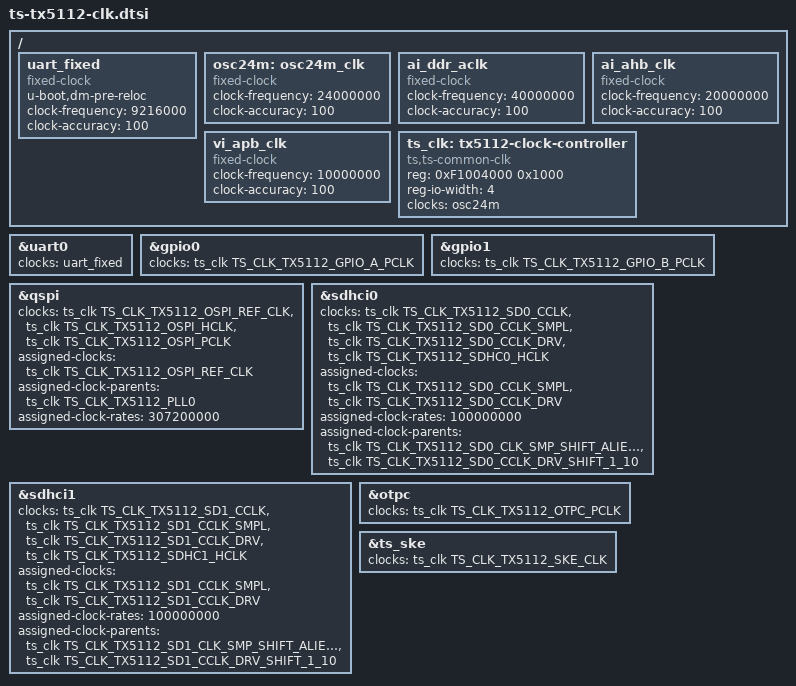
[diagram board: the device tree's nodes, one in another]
// SPDX-License-Identifier: GPL-2.0+
/*
 * dts file for tsingmicro tx51xx
 *
 * Copyright 2022 Beijing Tsingmicro Intelligent Technology Co.,Ltd.
 *
 */

#include <dt-bindings/clock/ts-tx5112-clk.h>
/ {
	uart_fixed: uart_fixed {
		u-boot,dm-pre-reloc;
		compatible = "fixed-clock";
		#clock-cells = <0>;
		clock-frequency = <9216000>;
		clock-accuracy = <100>;
	};
	osc24m: osc24m_clk {
		compatible = "fixed-clock";
		#clock-cells = <0>;
		clock-frequency = <24000000>;
		clock-accuracy = <100>;
	};

	ai_ddr_aclk: ai_ddr_aclk {
		compatible = "fixed-clock";
		#clock-cells = <0>;
		clock-frequency = <40000000>;
		clock-accuracy = <100>;
	};

	ai_ahb_clk: ai_ahb_clk {
			compatible = "fixed-clock";
			#clock-cells = <0>;
			clock-frequency = <20000000>;
			clock-accuracy = <100>;
	};

	vi_apb_clk: vi_apb_clk{
			compatible = "fixed-clock";
			#clock-cells = <0>;
			clock-frequency = <10000000>;
			clock-accuracy = <100>;
	};

	ts_clk: tx5112-clock-controller {
		reg = <0xF1004000 0x1000>;
		reg-io-width = <4>;
		#clock-cells = <1>;
		compatible = "ts,ts-common-clk";
		clocks = <&osc24m>;
	};
};
&uart0 {
	clocks = <&uart_fixed>;
};

&gpio0 {
	clocks = <&ts_clk TS_CLK_TX5112_GPIO_A_PCLK>;
	clock-names = "pclk";
};

&gpio1 {
	clocks = <&ts_clk TS_CLK_TX5112_GPIO_B_PCLK>;
	clock-names = "pclk";
};

&qspi {
	clocks = <&ts_clk TS_CLK_TX5112_OSPI_REF_CLK>, <&ts_clk TS_CLK_TX5112_OSPI_HCLK>, <&ts_clk TS_CLK_TX5112_OSPI_PCLK>;
	clock-names = "ospi_refclk", "ospi_hclk", "ospi_pclk";

	assigned-clocks = <&ts_clk TS_CLK_TX5112_OSPI_REF_CLK>;
	assigned-clock-parents = <&ts_clk TS_CLK_TX5112_PLL0>;
	assigned-clock-rates = <307200000>;
};

&sdhci0 {
	clocks = <&ts_clk TS_CLK_TX5112_SD0_CCLK>, <&ts_clk TS_CLK_TX5112_SD0_CCLK_SMPL>, <&ts_clk TS_CLK_TX5112_SD0_CCLK_DRV>, <&ts_clk TS_CLK_TX5112_SDHC0_HCLK>;
	clock-names = "ciu", "siu", "diu", "hiu";
	assigned-clocks = <&ts_clk TS_CLK_TX5112_SD0_CCLK>;
	assigned-clock-rates = <100000000>;
	assigned-clocks = <&ts_clk TS_CLK_TX5112_SD0_CCLK_SMPL>, <&ts_clk TS_CLK_TX5112_SD0_CCLK_DRV>;
	//assigned-clock-parents = <&ts_clk TS_CLK_TX5112_SD0_CLK_SMP_SHIFT_ALIEND>, <&ts_clk TS_CLK_TX5112_SD0_CLK_SMP_SHIFT_ALIEND>;
	assigned-clock-parents = <&ts_clk TS_CLK_TX5112_SD0_CLK_SMP_SHIFT_ALIEND>, <&ts_clk TS_CLK_TX5112_SD0_CCLK_DRV_SHIFT_1_10>;
};

&sdhci1 {
	clocks = <&ts_clk TS_CLK_TX5112_SD1_CCLK>, <&ts_clk TS_CLK_TX5112_SD1_CCLK_SMPL>, <&ts_clk TS_CLK_TX5112_SD1_CCLK_DRV>, <&ts_clk TS_CLK_TX5112_SDHC1_HCLK>;
	clock-names = "ciu", "siu", "diu", "hiu";
	assigned-clocks = <&ts_clk TS_CLK_TX5112_SD1_CCLK>;
	assigned-clock-rates = <100000000>;
	assigned-clocks = <&ts_clk TS_CLK_TX5112_SD1_CCLK_SMPL>, <&ts_clk TS_CLK_TX5112_SD1_CCLK_DRV>;
	assigned-clock-parents = <&ts_clk TS_CLK_TX5112_SD1_CLK_SMP_SHIFT_ALIEND>, <&ts_clk TS_CLK_TX5112_SD1_CCLK_DRV_SHIFT_1_10>;
};

&otpc {
	clocks = <&ts_clk TS_CLK_TX5112_OTPC_PCLK>;
	clock-names = "otpc_pclk";
};

&ts_ske {
	clocks = <&ts_clk TS_CLK_TX5112_SKE_CLK>;
	clock-names = "ske_clk";
};
